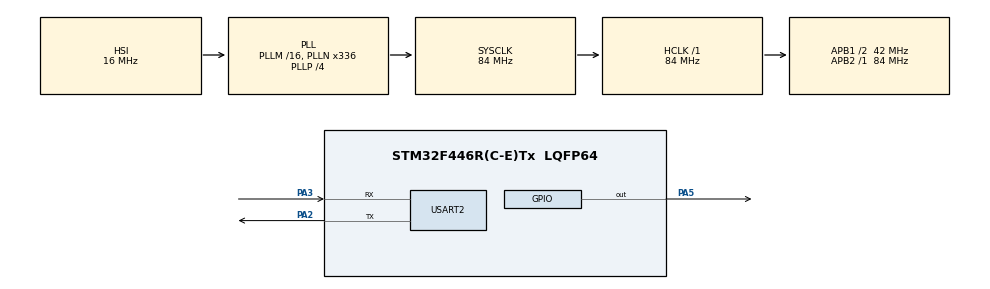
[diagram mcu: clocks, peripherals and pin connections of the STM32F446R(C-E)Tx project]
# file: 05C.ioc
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Mcu.Family=STM32F4
Mcu.Name=STM32F446R(C-E)Tx
Mcu.Package=LQFP64
NVIC.PriorityGroup=NVIC_PRIORITYGROUP_0
NVIC.USART2_IRQn=true\:0\:0\:false\:false\:true\:true\:true\:true
PA2.Mode=Asynchronous
PA2.Signal=USART2_TX
PA3.GPIO_PuPd=GPIO_PULLUP
PA3.Mode=Asynchronous
PA3.Signal=USART2_RX
PA5.Signal=GPIO_Output
ProjectManager.HeapSize=0x200
ProjectManager.StackSize=0x400
ProjectManager.TargetToolchain=STM32CubeIDE
RCC.AHBFreq_Value=84000000
RCC.APB1CLKDivider=RCC_HCLK_DIV2
RCC.APB1Freq_Value=42000000
RCC.APB1TimFreq_Value=84000000
RCC.APB2Freq_Value=84000000
RCC.APB2TimFreq_Value=84000000
RCC.CortexFreq_Value=84000000
RCC.FLatency-AdvancedSettings=FLASH_LATENCY_2
RCC.HCLKFreq_Value=84000000
RCC.HSE_VALUE=8000000
RCC.HSI_VALUE=16000000
RCC.LSE_VALUE=32768
RCC.PLLN=336
RCC.PLLP=RCC_PLLP_DIV4
RCC.SYSCLKFreq_VALUE=84000000
RCC.SYSCLKSource=RCC_SYSCLKSOURCE_PLLCLK
RCC.USBFreq_Value=168000000
RCC.VCOOutputFreq_Value=336000000
USART2.VirtualMode=VM_ASYNC
board=NUCLEO-F446RE

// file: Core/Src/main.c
/* USER CODE BEGIN Header */
/**
  ******************************************************************************
  * @file           : main.c
  * @brief          : Main program body
  ******************************************************************************
  * @attention
  *
  * Copyright (c) 2025 STMicroelectronics.
  * All rights reserved.
  *
  * This software is licensed under terms that can be found in the LICENSE file
  * in the root directory of this software component.
  * If no LICENSE file comes with this software, it is provided AS-IS.
  *
  ******************************************************************************
  */
/* USER CODE END Header */
#include "main.h"

/* USER CODE BEGIN Includes */

#include <stdio.h>
#include <string.h>

/* USER CODE END Includes */

UART_HandleTypeDef huart2;

/* USER CODE BEGIN PV */

char chTXBuffer[100];

uint16_t ui16Timer, ui16Counts, ui16CountsOld;

char chRXBuffer[100];
uint8_t ui8Error;

/* USER CODE END PV */

void SystemClock_Config(void);
static void MX_GPIO_Init(void);
static void MX_USART2_UART_Init(void);

int main(void)
{

  /* MCU Configuration--------------------------------------------------------*/

  /* Reset of all peripherals, Initializes the Flash interface and the Systick. */
  HAL_Init();

  /* Configure the system clock */
  SystemClock_Config();

  /* Initialize all configured peripherals */
  MX_GPIO_Init();
  MX_USART2_UART_Init();
  /* USER CODE BEGIN 2 */

//  sprintf(chTXBuffer,"This is the first Data from STM32F446...\r\n");
//  HAL_UART_Transmit(&huart2, (uint8_t *)chTXBuffer, strlen(chTXBuffer), HAL_MAX_DELAY);

   HAL_UART_Receive_IT(&huart2, (uint8_t *)chRXBuffer, 5);

  /* USER CODE END 2 */

  /* Infinite loop */
  /* USER CODE BEGIN WHILE */
  while (1)
  {

//	  if(ui16CountsOld != ui16Counts)
//	  {
//		  ui16CountsOld = ui16Counts;
//		  sprintf(chTXBuffer,"The value is %d...(in interrupt mode) \r\n",ui16Counts);
//		  HAL_UART_Transmit_IT(&huart2, (uint8_t *)chTXBuffer, strlen(chTXBuffer));
//	  }

//	  if(ui16CountsOld != ui16Counts)
//	  {
//		  ui16CountsOld = ui16Counts;
//		  sprintf(chTXBuffer,"The value is %d...\r\n",ui16Counts);
//		  HAL_UART_Transmit(&huart2, (uint8_t *)chTXBuffer, strlen(chTXBuffer), HAL_MAX_DELAY);
//
//
//
//		  ui8Error = HAL_UART_Receive(&huart2, (uint8_t *)chRXBuffer, 5, 4000);
//
//		  if(ui8Error != HAL_OK)
//		  {
//			  sprintf(chTXBuffer,"RX Error [%d]...\r\n",ui8Error);
//			  HAL_UART_Transmit(&huart2, (uint8_t *)chTXBuffer, strlen(chTXBuffer), HAL_MAX_DELAY);
//		  }
//		  else
//		  {
//			  chRXBuffer[5] = 0;
//			  sprintf(chTXBuffer,"Received data: [%s]...\r\n",chRXBuffer);
//			  HAL_UART_Transmit(&huart2, (uint8_t *)chTXBuffer, strlen(chTXBuffer), HAL_MAX_DELAY);
//		  }
//	  }

    /* USER CODE END WHILE */

  }
}

void SystemClock_Config(void)
{
  RCC_OscInitTypeDef RCC_OscInitStruct = {0};
  RCC_ClkInitTypeDef RCC_ClkInitStruct = {0};

  /** Configure the main internal regulator output voltage
  */
  __HAL_RCC_PWR_CLK_ENABLE();
  __HAL_PWR_VOLTAGESCALING_CONFIG(PWR_REGULATOR_VOLTAGE_SCALE3);

  /** Initializes the RCC Oscillators according to the specified parameters
  * in the RCC_OscInitTypeDef structure.
  */
  RCC_OscInitStruct.OscillatorType = RCC_OSCILLATORTYPE_HSI;
  RCC_OscInitStruct.HSIState = RCC_HSI_ON;
  RCC_OscInitStruct.HSICalibrationValue = RCC_HSICALIBRATION_DEFAULT;
  RCC_OscInitStruct.PLL.PLLState = RCC_PLL_ON;
  RCC_OscInitStruct.PLL.PLLSource = RCC_PLLSOURCE_HSI;
  RCC_OscInitStruct.PLL.PLLM = 16;
  RCC_OscInitStruct.PLL.PLLN = 336;
  RCC_OscInitStruct.PLL.PLLP = RCC_PLLP_DIV4;
  RCC_OscInitStruct.PLL.PLLQ = 2;
  RCC_OscInitStruct.PLL.PLLR = 2;
  if (HAL_RCC_OscConfig(&RCC_OscInitStruct) != HAL_OK)
  {
    Error_Handler();
  }

  /** Initializes the CPU, AHB and APB buses clocks
  */
  RCC_ClkInitStruct.ClockType = RCC_CLOCKTYPE_HCLK|RCC_CLOCKTYPE_SYSCLK
                              |RCC_CLOCKTYPE_PCLK1|RCC_CLOCKTYPE_PCLK2;
  RCC_ClkInitStruct.SYSCLKSource = RCC_SYSCLKSOURCE_PLLCLK;
  RCC_ClkInitStruct.AHBCLKDivider = RCC_SYSCLK_DIV1;
  RCC_ClkInitStruct.APB1CLKDivider = RCC_HCLK_DIV2;
  RCC_ClkInitStruct.APB2CLKDivider = RCC_HCLK_DIV1;

  if (HAL_RCC_ClockConfig(&RCC_ClkInitStruct, FLASH_LATENCY_2) != HAL_OK)
  {
    Error_Handler();
  }
}

static void MX_USART2_UART_Init(void)
{

  huart2.Instance = USART2;
  huart2.Init.BaudRate = 115200;
  huart2.Init.WordLength = UART_WORDLENGTH_8B;
  huart2.Init.StopBits = UART_STOPBITS_1;
  huart2.Init.Parity = UART_PARITY_NONE;
  huart2.Init.Mode = UART_MODE_TX_RX;
  huart2.Init.HwFlowCtl = UART_HWCONTROL_NONE;
  huart2.Init.OverSampling = UART_OVERSAMPLING_16;
  if (HAL_UART_Init(&huart2) != HAL_OK)
  {
    Error_Handler();
  }

}

static void MX_GPIO_Init(void)
{
  GPIO_InitTypeDef GPIO_InitStruct = {0};

  /* GPIO Ports Clock Enable */
  __HAL_RCC_GPIOA_CLK_ENABLE();

  /*Configure GPIO pin Output Level */
  HAL_GPIO_WritePin(GPIOA, GPIO_PIN_5, GPIO_PIN_RESET);

  /*Configure GPIO pin : PA5 */
  GPIO_InitStruct.Pin = GPIO_PIN_5;
  GPIO_InitStruct.Mode = GPIO_MODE_OUTPUT_PP;
  GPIO_InitStruct.Pull = GPIO_NOPULL;
  GPIO_InitStruct.Speed = GPIO_SPEED_FREQ_LOW;
  HAL_GPIO_Init(GPIOA, &GPIO_InitStruct);

}

/* USER CODE BEGIN 4 */
void HAL_UART_TxCpltCallback(UART_HandleTypeDef *huart)
{
  /* Prevent unused argument(s) compilation warning */
  UNUSED(huart);
  /* NOTE: This function should not be modified, when the callback is needed,
           the HAL_UART_TxCpltCallback could be implemented in the user file
   */

  HAL_GPIO_TogglePin(GPIOA, GPIO_PIN_5);
}

void HAL_UART_RxCpltCallback(UART_HandleTypeDef *huart)
{
  /* Prevent unused argument(s) compilation warning */
  UNUSED(huart);
  /* NOTE: This function should not be modified, when the callback is needed,
           the HAL_UART_RxCpltCallback could be implemented in the user file
   */
  chRXBuffer[5] = 0;
  sprintf(chTXBuffer,"Received characters = [%s]...\r\n",chRXBuffer);
  HAL_UART_Transmit(huart, (uint8_t*)chTXBuffer, strlen(chTXBuffer), HAL_MAX_DELAY);

  HAL_UART_Receive_IT(&huart2, (uint8_t *)chRXBuffer, 5);
}

/* USER CODE END 4 */

void Error_Handler(void)
{
  __disable_irq();
  while (1)
  {
  }
}
